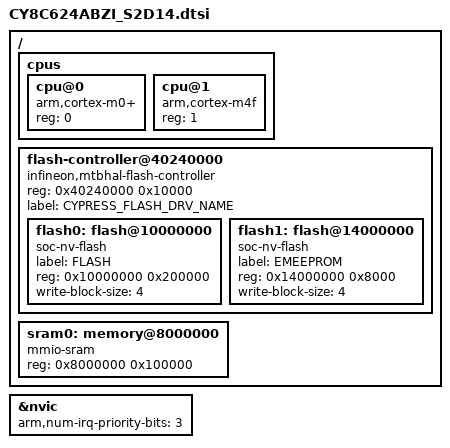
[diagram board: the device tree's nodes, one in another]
/*
 * Copyright (c) 2021, Cypress Semiconductor
 * SPDX-License-Identifier: Apache-2.0
 */

#include "../psoc6_02/psoc6_02.124-bga.dtsi"


/ {
    cpus {
        #address-cells = <1>;
        #size-cells = <0>;

        cpu@0 {
            device_type = "cpu";
            compatible = "arm,cortex-m0+";
            reg = <0>;
        };
        cpu@1 {
            device_type = "cpu";
            compatible = "arm,cortex-m4f";
            reg = <1>;
        };
    };

    flash-controller@40240000 {
        compatible = "infineon,mtbhal-flash-controller";
        reg = < 0x40240000 0x10000 >;
        #address-cells = <1>;
        #size-cells = <1>;
        label = "CYPRESS_FLASH_DRV_NAME";

        flash0: flash@10000000 {
            compatible = "soc-nv-flash"; 
            label = "FLASH"; 
            reg = <0x10000000 0x200000>;
            write-block-size = <4>;
        };
        flash1: flash@14000000 {
            compatible = "soc-nv-flash";
            label = "EMEEPROM"; 
            reg = <0x14000000 0x8000>;
            write-block-size = <4>;
        };
    };

    sram0: memory@8000000 {
        compatible = "mmio-sram"; 
        reg = <0x8000000 0x100000>;
    };

};



&nvic {
    arm,num-irq-priority-bits = <3>;
};
